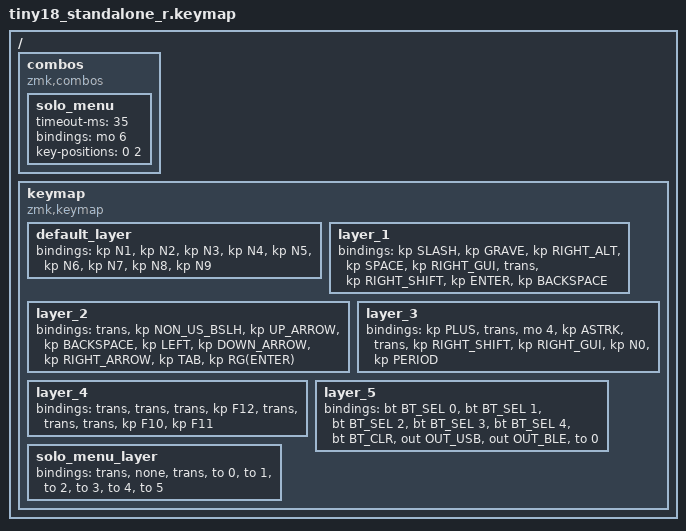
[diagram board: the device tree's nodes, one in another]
#include <behaviors.dtsi>
#include <dt-bindings/zmk/keys.h>
#include <dt-bindings/zmk/bt.h>
#include <dt-bindings/zmk/outputs.h>

/ {
    combos {
        compatible = "zmk,combos";
        solo_menu {
            timeout-ms = <35>;
            bindings = <&mo 6>;
            key-positions = <0 2>;
        };
    };
    keymap {
        compatible = "zmk,keymap";
        default_layer {
            bindings = <&kp N1  &kp N2  &kp N3  &kp N4  &kp N5  &kp N6  &kp N7  &kp N8  &kp N9>;
        };
        layer_1 {
            bindings = <&kp SLASH  &kp GRAVE  &kp RIGHT_ALT  &kp SPACE  &kp RIGHT_GUI  &trans  &kp RIGHT_SHIFT  &kp ENTER  &kp BACKSPACE>;
        };
        layer_2 {
            bindings = <&trans  &kp NON_US_BSLH  &kp UP_ARROW  &kp BACKSPACE  &kp LEFT  &kp DOWN_ARROW  &kp RIGHT_ARROW  &kp TAB  &kp RG(ENTER)>;
        };
        layer_3 {
            bindings = <&kp PLUS  &trans  &mo 4  &kp ASTRK  &trans  &kp RIGHT_SHIFT  &kp RIGHT_GUI  &kp N0  &kp PERIOD>;
        };
        layer_4 {
            bindings = <&trans  &trans  &trans  &kp F12  &trans  &trans  &trans  &kp F10  &kp F11>;
        };
        layer_5 {
            bindings = <&bt BT_SEL 0  &bt BT_SEL 1  &bt BT_SEL 2  &bt BT_SEL 3  &bt BT_SEL 4  &bt BT_CLR  &out OUT_USB  &out OUT_BLE  &to 0>;
        };
        solo_menu_layer {
            bindings = <&trans &none &trans &to 0 &to 1 &to 2 &to 3 &to 4 &to 5>;
        };
    };
};
